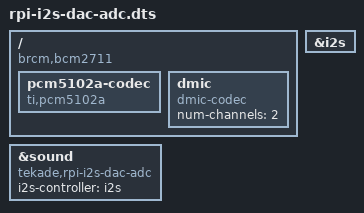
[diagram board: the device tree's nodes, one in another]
// Definitions for TeKaDe rpi-i2s-dac-adc
/dts-v1/;
/plugin/;

/ {
	compatible = "brcm,bcm2711";

	fragment@0 {
		target = <&i2s>;
		__overlay__ {
			status = "okay";
		};
	};

	fragment@1 {
		target-path = "/";
		__overlay__ {
			pcm5102a-codec {
				#sound-dai-cells = <0>;
				compatible = "ti,pcm5102a";
				status = "okay";
			};
		};
	};

	fragment@2 {
		target-path = "/";
		__overlay__ {
			dmic {
				#sound-dai-cells = <0>;
				compatible = "dmic-codec";
				num-channels = <2>;
				status = "okay";
			};
		};
	};

	fragment@3 {
		target = <&sound>;
		__overlay__ {
			compatible = "tekade,rpi-i2s-dac-adc";
			i2s-controller = <&i2s>;
			status = "okay";
		};
	};
};
